# RZN2H register map
Vendor: Renesas Electronics Corporation; Series: RZN; File version: 1.00.00
CPU: other r0p0, little endian, MPU, no FPU, VTOR, 4 interrupt priority bits, 624 interrupts
Registers are 32-bit, read-write, reset 0x0 unless marked. A register's access mark holds for its fields unless they carry their own. Offsets are from the block's base; [hi:lo] are bit positions; {n}, {i} and the like mark numbered series; 'fields as' and 'values as' point back to an identical list.

## GPT09_0 (part 1 of 2) — General PWM Timer 09
Base 0x80000000
Same registers: GPT09_1 0x80000100, GPT09_2 0x80000200, GPT09_3 0x80000300, GPT09_4 0x80000400, GPT09_5 0x80000500, GPT09_6 0x80000600, GPT00_0 0x90002000, GPT00_1 0x90002100, GPT00_2 0x90002200, GPT00_3 0x90002300, GPT00_4 0x90002400, GPT01_0 0x90003000, GPT01_1 0x90003100, GPT01_2 0x90003200, GPT01_3 0x90003300, GPT01_4 0x90003400, GPT02_0 0x90004000, GPT02_1 0x90004100, GPT02_2 0x90004200, GPT02_3 0x90004300, GPT02_4 0x90004400, GPT03_0 0x90005000, GPT03_1 0x90005100, GPT03_2 0x90005200, GPT03_3 0x90005300, GPT03_4 0x90005400, GPT04_0 0x90006000, GPT04_1 0x90006100, GPT04_2 0x90006200, GPT04_3 0x90006300, GPT04_4 0x90006400, GPT05_0 0x90007000, GPT05_1 0x90007100, GPT05_2 0x90007200, GPT05_3 0x90007300, GPT05_4 0x90007400, GPT06_0 0x90100000, GPT06_1 0x90100100, GPT06_2 0x90100200, GPT06_3 0x90100300, GPT06_4 0x90100400, GPT07_0 0x90101000, GPT07_1 0x90101100, GPT07_2 0x90101200, GPT07_3 0x90101300, GPT07_4 0x90101400, GPT08_0 0x90102000, GPT08_1 0x90102100, GPT08_2 0x90102200, GPT08_3 0x90102300, GPT08_4 0x90102400
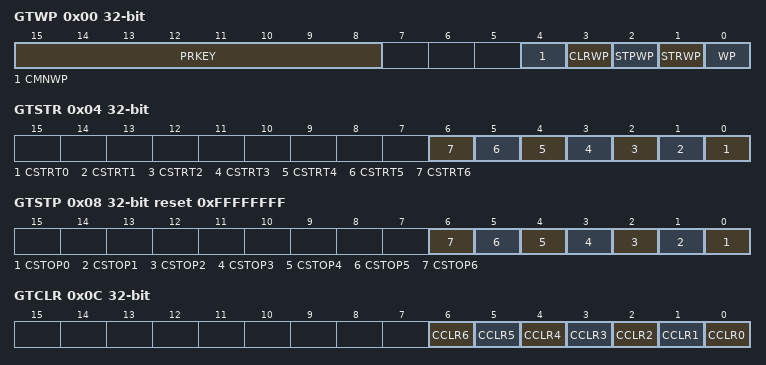
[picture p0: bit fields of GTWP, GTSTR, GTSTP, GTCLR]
0x00 GTWP — General PWM Timer Write-Protection Register
  [15:8] PRKEY wo — GTWP Key Code
  [4] CMNWP — Common Register Write Disabled
    0=Write to the register is enabled; 1=Write to the register is disabled
  [3] CLRWP — GTCLR.CCLR Bit Write Disabled
    0=Write to the bit is enabled; 1=Write to the bit is disabled
  [2] STPWP — GTSTP.CSTOP Bit Write Disabled
    values as CLRWP
  [1] STRWP — GTSTR.CSTRT Bit Write Disabled
    values as CLRWP
  [0] WP — Register Write Disabled
    values as CMNWP
0x04 GTSTR — General PWM Timer Software Start Register
  [all] fields
    0=(Reading) The counter is stopped (Writing) No effect; 1=(Reading) The counter is running (Writing) The counter starts running
  [n] CSTRT{n} (n=0..6) — Channel {n} Count Start
0x08 GTSTP reset 0xFFFFFFFF — General PWM Timer Software Stop Register
  [all] fields
    0=(Reading) The counter is operating (Writing) No effect; 1=(Reading) The counter is stopped (Writing) The counter is stopped
  [n] CSTOP{n} (n=0..6) — Channel {n} Count Stop
0x0C GTCLR wo — General PWM Timer Software Clear Register
  [all] fields
    0=The counter is not cleared; 1=The counter is cleared
  [n] CCLR{n} (n=0..6) — Channel {n} Count Clear
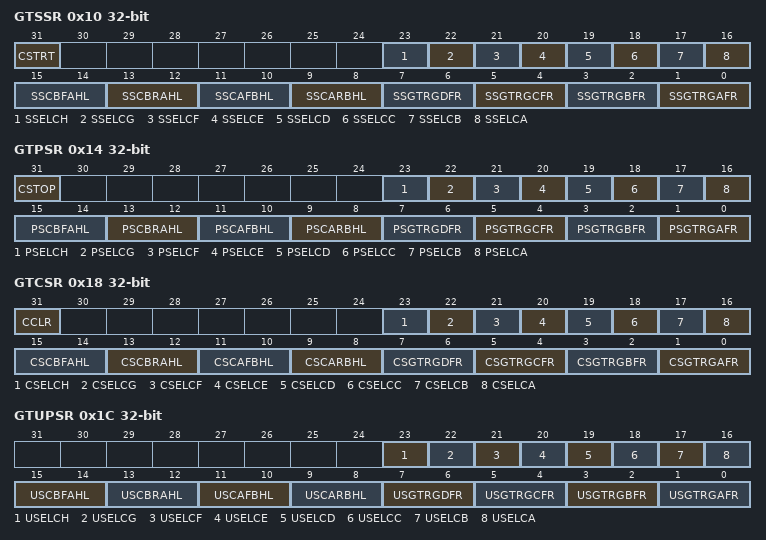
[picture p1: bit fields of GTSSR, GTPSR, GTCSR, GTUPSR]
0x10 GTSSR — General PWM Timer Start Source Select Register
  [31] CSTRT — Software Source Count Start Enable
    0=Disables count start by the GTSTR register; 1=Enables count start by the GTSTR register
  [23] SSELCH
    0=Disables count start by the event H input; 1=Enables count start by the event H input
  [22] SSELCG
    0=Disables count start by the event G input; 1=Enables count start by the event G input
  [21] SSELCF
    0=Disables count start by the event F input; 1=Enables count start by the event F input
  [20] SSELCE
    0=Disables count start by the event E input; 1=Enables count start by the event E input
  [19] SSELCD
    0=Disables count start by the event D input; 1=Enables count start by the event D input
  [18] SSELCC
    0=Disables count start by the event C input; 1=Enables count start by the event C input
  [17] SSELCB
    0=Disables count start by the event B input; 1=Enables count start by the event B input
  [16] SSELCA
    0=Disables count start by the event A input; 1=Enables count start by the event A input
  [15:14] SSCBFAHL
    0=Falling edge of the GTIOCm_nB signal is not used as a trigger to start counting; 1=The counter starts at a falling edge of the GTIOCm_nB signal while the GTIOCm_nA pin is driven low; 2=The counter starts at a falling edge of the GTIOCm_nB signal while the GTIOCm_nA pin is driven high; 3=The counter starts at a falling edge of the GTIOCm_nB signal
  [13:12] SSCBRAHL
    0=Rising edge of the GTIOCm_nB signal is not used as a trigger to start counting; 1=The counter starts at a rising edge of the GTIOCm_nB signal while the GTIOCm_nA pin is driven low; 2=The counter starts at a rising edge of the GTIOCm_nB signal while the GTIOCm_nA pin is driven high; 3=The counter starts at a rising edge of the GTIOCm_nB signal
  [11:10] SSCAFBHL
    0=Falling edge of the GTIOCm_nA signal is not used as a trigger to start counting; 1=The counter starts at a falling edge of the GTIOCm_nA signal while the GTIOCm_nB pin is driven low; 2=The counter starts at a falling edge of the GTIOCm_nA signal while the GTIOCm_nB pin is driven high; 3=The counter starts at a falling edge of the GTIOCm_nA signal
  [9:8] SSCARBHL
    0=Rising edge of the GTIOCm_nA signal is not used as a trigger to start counting; 1=The counter starts at a rising edge of the GTIOCm_nA signal while the GTIOCm_nB pin is driven low; 2=The counter starts at a rising edge of the GTIOCm_nA signal while the GTIOCm_nB pin is driven high; 3=The counter starts at a rising edge of the GTIOCm_nA signal
  [7:6] SSGTRGDFR
    0=The GTETRGD signal is not used as a trigger to start counting; 1=The counter starts at a rising edge of the GTETRGD signal; 2=The counter starts at a falling edge of the GTETRGD signal; 3=The counter starts at both edges of the GTETRGD signal
  [5:4] SSGTRGCFR
    0=The GTETRGC signal is not used as a trigger to start counting; 1=The counter starts at a rising edge of the GTETRGC signal; 2=The counter starts at a falling edge of the GTETRGC signal; 3=The counter starts at both edges of the GTETRGC signal
  [3:2] SSGTRGBFR
    0=The GTETRGB signal is not used as a trigger to start counting; 1=The counter starts at a rising edge of the GTETRGB signal; 2=The counter starts at a falling edge of the GTETRGB signal; 3=The counter starts at both edges of the GTETRGB signal
  [1:0] SSGTRGAFR
    0=The GTETRGA signal is not used as a trigger to start counting; 1=The counter starts at a rising edge of the GTETRGA signal; 2=The counter starts at a falling edge of the GTETRGA signal; 3=The counter starts at both edges of the GTETRGA signal
0x14 GTPSR — General PWM Timer Stop Source Select Register
  [31] CSTOP
    0=Disables count stop by the GTSTP register; 1=Enables count stop by the GTSTP register
  [23] PSELCH
    0=Disables count stop by the event H input; 1=Enables count stop by the event H input
  [22] PSELCG
    0=Disables count stop by the event G input; 1=Enables count stop by the event G input
  [21] PSELCF
    0=Disables count stop by the event F input; 1=Enables count stop by the event F input
  [20] PSELCE
    0=Disables count stop by the event E input; 1=Enables count stop by the event E input
  [19] PSELCD
    0=Disables count stop by the event D input; 1=Enables count stop by the event D input
  [18] PSELCC
    0=Disables count stop by the event C input; 1=Enables count stop by the event C input
  [17] PSELCB
    0=Disables count stop by the event B input; 1=Enables count stop by the event B input
  [16] PSELCA
    0=Disables count stop by the event A input; 1=Enables count stop by the event A input
  [15:14] PSCBFAHL
    0=Falling edge of the GTIOCm_nB signal is not used as a trigger to stop counting; 1=The counter stops at a falling edge of the GTIOCm_nB signal while the GTIOCm_nA pin is driven low; 2=The counter stops at a falling edge of the GTIOCm_nB signal while the GTIOCm_nA pin is driven high; 3=The counter stops at a falling edge of the GTIOCm_nB signal
  [13:12] PSCBRAHL
    0=Rising edge of the GTIOCm_nB signal is not used as a trigger to stop counting; 1=The counter stops at a rising edge of the GTIOCm_nB signal while the GTIOCm_nA pin is driven low; 2=The counter stops at a rising edge of the GTIOCm_nB signal while the GTIOCm_nA pin is driven high; 3=The counter stops at a rising edge of the GTIOCm_nB signal
  [11:10] PSCAFBHL
    0=Falling edge of the GTIOCm_nA signal is not used as a trigger to stop counting; 1=The counter stops at a falling edge of the GTIOCm_nA signal while the GTIOCm_nB pin is driven low; 2=The counter stops at a falling edge of the GTIOCm_nA signal while the GTIOCm_nB pin is driven high; 3=The counter stops at a falling edge of the GTIOCm_nA signal
  [9:8] PSCARBHL
    0=Rising edge of the GTIOCm_nA signal is not used as a trigger to stop counting; 1=The counter stops at a rising edge of the GTIOCm_nA signal while the GTIOCm_nB pin is driven low; 2=The counter stops at a rising edge of the GTIOCm_nA signal while the GTIOCm_nB pin is driven high; 3=The counter stops at a rising edge of the GTIOCm_nA signal
  [7:6] PSGTRGDFR
    0=The GTETRGD signal is not used as a trigger to stop counting; 1=The counter stops at a rising edge of the GTETRGD signal; 2=The counter stops at a falling edge of the GTETRGD signal; 3=The counter stops at both edges of the GTETRGD signal
  [5:4] PSGTRGCFR
    0=The GTETRGC signal is not used as a trigger to stop counting; 1=The counter stops at a rising edge of the GTETRGC signal; 2=The counter stops at a falling edge of the GTETRGC signal; 3=The counter stops at both edges of the GTETRGC signal
  [3:2] PSGTRGBFR
    0=The GTETRGB signal is not used as a trigger to stop counting; 1=The counter stops at a rising edge of the GTETRGB signal; 2=The counter stops at a falling edge of the GTETRGB signal; 3=The counter stops at both edges of the GTETRGB signal
  [1:0] PSGTRGAFR
    0=The GTETRGA signal is not used as a trigger to stop counting; 1=The counter stops at a rising edge of the GTETRGA signal; 2=The counter stops at a falling edge of the GTETRGA signal; 3=The counter stops at both edges of the GTETRGA signal
0x18 GTCSR — General PWM Timer Clear Source Select Register
  [31] CCLR
    0=Disables counter clear by the GTCLR register; 1=Enables counter clear by the GTCLR register
  [23] CSELCH
    0=Disables counter clear by the event H input; 1=Enables counter clear by the event H input
  [22] CSELCG
    0=Disables counter clear by the event G input; 1=Enables counter clear by the event G input
  [21] CSELCF
    0=Disables counter clear by the event F input; 1=Enables counter clear by the event F input
  [20] CSELCE
    0=Disables counter clear by the event E input; 1=Enables counter clear by the event E input
  [19] CSELCD
    0=Disables counter clear by the event D input; 1=Enables counter clear by the event D input
  [18] CSELCC
    0=Disables counter clear by the event C input; 1=Enables counter clear by the event C input
  [17] CSELCB
    0=Disables counter clear by the event B input; 1=Enables counter clear by the event B input
  [16] CSELCA
    0=Disables counter clear by the event A input; 1=Enables counter clear by the event A input
  [15:14] CSCBFAHL
    0=Falling edge of the GTIOCm_nB signal is not used as a trigger to clear the counter; 1=The counter is cleared at a falling edge of the GTIOCm_nB signal while the GTIOCm_nA pin is driven low; 2=The counter is cleared at a falling edge of the GTIOCm_nB signal while the GTIOCm_nA pin is driven high; 3=The counter is cleared at a falling edge of the GTIOCm_nB signal
  [13:12] CSCBRAHL
    0=Rising edge of the GTIOCm_nB signal is not used as a trigger to clear the counter; 1=The counter is cleared at a rising edge of the GTIOCm_nB signal while the GTIOCm_nA pin is driven low; 2=The counter is cleared at a rising edge of the GTIOCm_nB signal while the GTIOCm_nA pin is driven high; 3=The counter is cleared at a rising edge of the GTIOCm_nB signal
  [11:10] CSCAFBHL
    0=Falling edge of the GTIOCm_nA signal is not used as a trigger to clear the counter; 1=The counter is cleared at a falling edge of the GTIOCm_nA signal while the GTIOCm_nB pin is driven low; 2=The counter is cleared at a falling edge of the GTIOCm_nA signal while the GTIOCm_nB pin is driven high; 3=The counter is cleared at a falling edge of the GTIOCm_nA signal
  [9:8] CSCARBHL
    0=Rising edge of the GTIOCm_nA signal is not used as a trigger to clear the counter; 1=The counter is cleared at a rising edge of the GTIOCm_nA signal while the GTIOCm_nB pin is driven low; 2=The counter is cleared at a rising edge of the GTIOCm_nA signal while the GTIOCm_nB pin is driven high; 3=The counter is cleared at a rising edge of the GTIOCm_nA signal
  [7:6] CSGTRGDFR
    0=The GTETRGD signal is not used as a trigger to clear the counter; 1=The counter is cleared at a rising edge of the GTETRGD signal; 2=The counter is cleared at a falling edge of the GTETRGD signal; 3=The counter is cleared at both edges of the GTETRGD signal
  [5:4] CSGTRGCFR
    0=The GTETRGC signal is not used as a trigger to clear the counter; 1=The counter is cleared at a rising edge of the GTETRGC signal; 2=The counter is cleared at a falling edge of the GTETRGC signal; 3=The counter is cleared at both edges of the GTETRGC signal
  [3:2] CSGTRGBFR
    0=The GTETRGB signal is not used as a trigger to clear the counter; 1=The counter is cleared at a rising edge of the GTETRGB signal; 2=The counter is cleared at a falling edge of the GTETRGB signal; 3=The counter is cleared at both edges of the GTETRGB signal
  [1:0] CSGTRGAFR
    0=The GTETRGA signal is not used as a trigger to clear the counter; 1=The counter is cleared at a rising edge of the GTETRGA signal; 2=The counter is cleared at a falling edge of the GTETRGA signal; 3=The counter is cleared at both edges of the GTETRGA signal
0x1C GTUPSR — General PWM Timer Count-Up Source Select Register
  [23] USELCH
    0=Disables count-up by the event H input; 1=Enables count-up by the event H input
  [22] USELCG
    0=Disables count-up by the event G input; 1=Enables count-up by the event G input
  [21] USELCF
    0=Disables count-up by the event F input; 1=Enables count-up by the event F input
  [20] USELCE
    0=Disables count-up by the event E input; 1=Enables count-up by the event E input
  [19] USELCD
    0=Disables count-up by the event D input; 1=Enables count-up by the event D input
  [18] USELCC
    0=Disables count-up by the event C input; 1=Enables count-up by the event C input
  [17] USELCB
    0=Disables count-up by the event B input; 1=Enables count-up by the event B input
  [16] USELCA
    0=Disables count-up by the event A input; 1=Enables count-up by the event A input
  [15:14] USCBFAHL
    0=Falling edge of the GTIOCm_nB signal is not used as a trigger to increment the counter; 1=The counter is incremented at a falling edge of the GTIOCm_nB signal while the GTIOCm_nA pin is driven low; 2=The counter is incremented at a falling edge of the GTIOCm_nB signal while the GTIOCm_nA pin is driven high; 3=The counter is incremented at a falling edge of the GTIOCm_nB signal
  [13:12] USCBRAHL
    0=Rising edge of the GTIOCm_nB signal is not used as a trigger to increment the counter; 1=The counter is incremented at a rising edge of the GTIOCm_nB signal while the GTIOCm_nA pin is driven low; 2=The counter is incremented at a rising edge of the GTIOCm_nB signal while the GTIOCm_nA pin is driven high; 3=The counter is incremented at a rising edge of the GTIOCm_nB signal
  [11:10] USCAFBHL
    0=Falling edge of the GTIOCm_nA signal is not used as a trigger to increment the counter; 1=The counter is incremented at a falling edge of the GTIOCm_nA signal while the GTIOCm_nB pin is driven low; 2=The counter is incremented at a falling edge of the GTIOCm_nA signal while the GTIOCm_nB pin is driven high; 3=The counter is incremented at a falling edge of the GTIOCm_nA signal
  [9:8] USCARBHL
    0=Rising edge of the GTIOCm_nA signal is not used as a trigger to increment the counter; 1=The counter is incremented at a rising edge of the GTIOCm_nA signal while the GTIOCm_nB pin is driven low; 2=The counter is incremented at a rising edge of the GTIOCm_nA signal while the GTIOCm_nB pin is driven high; 3=The counter is incremented at a rising edge of the GTIOCm_nA signal
  [7:6] USGTRGDFR
    0=The GTETRGD signal is not used as a trigger to increment the counter; 1=The counter is incremented at a rising edge of the GTETRGD signal; 2=The counter is incremented at a falling edge of the GTETRGD signal; 3=The counter is incremented at both edges of the GTETRGD signal
  [5:4] USGTRGCFR
    0=The GTETRGC signal is not used as a trigger to increment the counter; 1=The counter is incremented at a rising edge of the GTETRGC signal; 2=The counter is incremented at a falling edge of the GTETRGC signal; 3=The counter is incremented at both edges of the GTETRGC signal
  [3:2] USGTRGBFR
    0=The GTETRGB signal is not used as a trigger to increment the counter; 1=The counter is incremented at a rising edge of the GTETRGB signal; 2=The counter is incremented at a falling edge of the GTETRGB signal; 3=The counter is incremented at both edges of the GTETRGB signal
  [1:0] USGTRGAFR
    0=The GTETRGA signal is not used as a trigger to increment the counter; 1=The counter is incremented at a rising edge of the GTETRGA signal; 2=The counter is incremented at a falling edge of the GTETRGA signal; 3=The counter is incremented at both edges of the GTETRGA signal
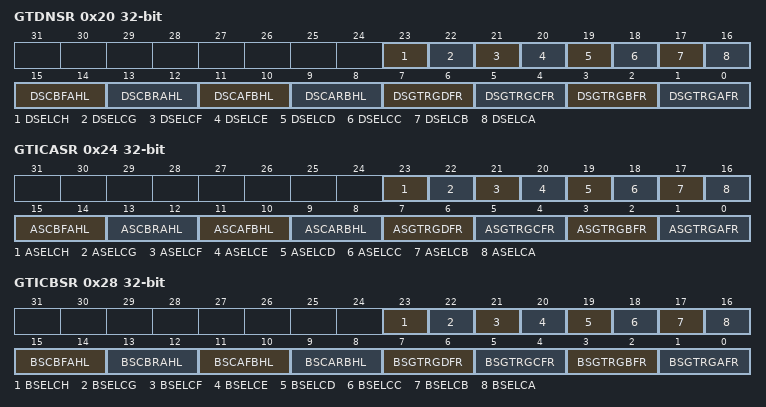
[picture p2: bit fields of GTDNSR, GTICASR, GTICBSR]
0x20 GTDNSR — General PWM Timer Count-Down Source Select Register
  [23] DSELCH
    0=Disables count-down by the event H input; 1=Enables count-down by the event H input
  [22] DSELCG
    0=Disables count-down by the event G input; 1=Enables count-down by the event G input
  [21] DSELCF
    0=Disables count-down by the event F input; 1=Enables count-down by the event F input
  [20] DSELCE
    0=Disables count-down by the event E input; 1=Enables count-down by the event E input
  [19] DSELCD
    0=Disables count-down by the event D input; 1=Enables count-down by the event D input
  [18] DSELCC
    0=Disables count-down by the event C input; 1=Enables count-down by the event C input
  [17] DSELCB
    0=Disables count-down by the event B input; 1=Enables count-down by the event B input
  [16] DSELCA
    0=Disables count-down by the event A input; 1=Enables count-down by the event A input
  [15:14] DSCBFAHL
    0=Falling edge of the GTIOCm_nB signal is not used as a trigger to decrement the counter; 1=The counter is decremented at a falling edge of the GTIOCm_nB signal while the GTIOCm_nA pin is driven low; 2=The counter is decremented at a falling edge of the GTIOCm_nB signal while the GTIOCm_nA pin is driven high; 3=The counter is decremented at a falling edge of the GTIOCm_nB signal
  [13:12] DSCBRAHL
    0=Rising edge of the GTIOCm_nB signal is not used as a trigger to decrement the counter; 1=The counter is decremented at a rising edge of the GTIOCm_nB signal while the GTIOCm_nA pin is driven low; 2=The counter is decremented at a rising edge of the GTIOCm_nB signal while the GTIOCm_nA pin is driven high; 3=The counter is decremented at a rising edge of the GTIOCm_nB signal
  [11:10] DSCAFBHL
    0=Falling edge of the GTIOCm_nA signal is not used as a trigger to decrement the counter; 1=The counter is decremented at a falling edge of the GTIOCm_nA signal while the GTIOCm_nB pin is driven low; 2=The counter is decremented at a falling edge of the GTIOCm_nA signal while the GTIOCm_nB pin is driven high; 3=The counter is decremented at a falling edge of the GTIOCm_nA signal
  [9:8] DSCARBHL
    0=Rising edge of the GTIOCm_nA signal is not used as a trigger to decrement the counter; 1=The counter is decremented at a rising edge of the GTIOCm_nA signal while the GTIOCm_nB pin is driven low; 2=The counter is decremented at a rising edge of the GTIOCm_nA signal while the GTIOCm_nB pin is driven high; 3=The counter is decremented at a rising edge of the GTIOCm_nA signal
  [7:6] DSGTRGDFR
    0=The GTETRGD signal is not used as a trigger to decrement the counter; 1=The counter is decremented at a rising edge of the GTETRGD signal; 2=The counter is decremented at a falling edge of the GTETRGD signal; 3=The counter is decremented at both edges of the GTETRGD signal
  [5:4] DSGTRGCFR
    0=The GTETRGC signal is not used as a trigger to decrement the counter; 1=The counter is decremented at a rising edge of the GTETRGC signal; 2=The counter is decremented at a falling edge of the GTETRGC signal; 3=The counter is decremented at both edges of the GTETRGC signal
  [3:2] DSGTRGBFR
    0=The GTETRGB signal is not used as a trigger to decrement the counter; 1=The counter is decremented at a rising edge of the GTETRGB signal; 2=The counter is decremented at a falling edge of the GTETRGB signal; 3=The counter is decremented at both edges of the GTETRGB signal
  [1:0] DSGTRGAFR
    0=The GTETRGA signal is not used as a trigger to decrement the counter; 1=The counter is decremented at a rising edge of the GTETRGA signal; 2=The counter is decremented at a falling edge of the GTETRGA signal; 3=The counter is decremented at both edges of the GTETRGA signal
0x24 GTICASR — General PWM Timer Input Capture Source Select Register A
  [23] ASELCH
    0=Disables GTCCRA input capture by the event H input; 1=Enables GTCCRA input capture by the event H input
  [22] ASELCG
    0=Disables GTCCRA input capture by the event G input; 1=Enables GTCCRA input capture by the event G input
  [21] ASELCF
    0=Disables GTCCRA input capture by the event F input; 1=Enables GTCCRA input capture by the event F input
  [20] ASELCE
    0=Disables GTCCRA input capture by the event E input; 1=Enables GTCCRA input capture by the event E input
  [19] ASELCD
    0=Disables GTCCRA input capture by the event D input; 1=Enables GTCCRA input capture by the event D input
  [18] ASELCC
    0=Disables GTCCRA input capture by the event C input; 1=Enables GTCCRA input capture by the event C input
  [17] ASELCB
    0=Disables GTCCRA input capture by the event B input; 1=Enables GTCCRA input capture by the event B input
  [16] ASELCA
    0=Disables GTCCRA input capture by the event A input; 1=Enables GTCCRA input capture by the event A input
  [15:14] ASCBFAHL
    0=Falling edge of the GTIOCm_nB signal is not used as a trigger to capture the counter value in the GTCCRA register; 1=The counter value is captured in the GTCCRA register at a falling edge of the GTIOCm_nB signal while the GTIOCm_nA pin is driven low; 2=The counter value is captured in the GTCCRA register at a falling edge of the GTIOCm_nB signal while the GTIOCm_nA pin is driven high; 3=The counter value is captured in the GTCCRA register at a falling edge of the GTIOCm_nB signal
  [13:12] ASCBRAHL
    0=Rising edge of the GTIOCm_nB signal is not used as a trigger to capture the counter value in the GTCCRA register; 1=The counter value is captured in the GTCCRA register at a rising edge of the GTIOCm_nB signal while the GTIOCm_nA pin is driven low; 2=The counter value is captured in the GTCCRA register at a rising edge of the GTIOCm_nB signal while the GTIOCm_nA pin is driven high; 3=The counter value is captured in the GTCCRA register at a rising edge of the GTIOCm_nB signal
  [11:10] ASCAFBHL
    0=Falling edge of the GTIOCm_nA signal is not used as a trigger to capture the counter value in the GTCCRA register; 1=The counter value is captured in the GTCCRA register at a falling edge of the GTIOCm_nA signal while the GTIOCm_nB pin is driven low; 2=The counter value is captured in the GTCCRA register at a falling edge of the GTIOCm_nA signal while the GTIOCm_nB pin is driven high; 3=The counter value is captured in the GTCCRA register at a falling edge of the GTIOCm_nA signal
  [9:8] ASCARBHL
    0=Rising edge of the GTIOCm_nA signal is not used as a trigger to capture the counter value in the GTCCRA register; 1=The counter value is captured in the GTCCRA register at a rising edge of the GTIOCm_nA signal while the GTIOCm_nB pin is driven low; 2=The counter value is captured in the GTCCRA register at a rising edge of the GTIOCm_nA signal while the GTIOCm_nB pin is driven high; 3=The counter value is captured in the GTCCRA register at a rising edge of the GTIOCm_nA signal
  [7:6] ASGTRGDFR
    0=The GTETRGD signal is not used as a trigger to capture the counter value in the GTCCRA register; 1=The counter value is captured in the GTCCRA register at a rising edge of the GTETRGD signal; 2=The counter value is captured in the GTCCRA register at a falling edge of the GTETRGD signal; 3=The counter value is captured in the GTCCRA register at both edges of the GTETRGD signal
  [5:4] ASGTRGCFR
    0=The GTETRGC signal is not used as a trigger to capture the counter value in the GTCCRA register; 1=The counter value is captured in the GTCCRA register at a rising edge of the GTETRGC signal; 2=The counter value is captured in the GTCCRA register at a falling edge of the GTETRGC signal; 3=The counter value is captured in the GTCCRA register at both edges of the GTETRGC signal
  [3:2] ASGTRGBFR
    0=The GTETRGB signal is not used as a trigger to capture the counter value in the GTCCRA register; 1=The counter value is captured in the GTCCRA register at a rising edge of the GTETRGB signal; 2=The counter value is captured in the GTCCRA register at a falling edge of the GTETRGB signal; 3=The counter value is captured in the GTCCRA register at both edges of the GTETRGB signal
  [1:0] ASGTRGAFR
    0=The GTETRGA signal is not used as a trigger to capture the counter value in the GTCCRA register; 1=The counter value is captured in the GTCCRA register at a rising edge of the GTETRGA signal; 2=The counter value is captured in the GTCCRA register at a falling edge of the GTETRGA signal; 3=The counter value is captured in the GTCCRA register at both edges of the GTETRGA signal
0x28 GTICBSR — General PWM Timer Input Capture Source Select Register B
  [23] BSELCH
    0=Disables GTCCRB input capture by the event H input; 1=Enables GTCCRB input capture by the event H input
  [22] BSELCG
    0=Disables GTCCRB input capture by the event G input; 1=Enables GTCCRB input capture by the event G input
  [21] BSELCF
    0=Disables GTCCRB input capture by the event F input; 1=Enables GTCCRB input capture by the event F input
  [20] BSELCE
    0=Disables GTCCRB input capture by the event E input; 1=Enables GTCCRB input capture by the event E input
  [19] BSELCD
    0=Disables GTCCRB input capture by the event D input; 1=Enables GTCCRB input capture by the event D input
  [18] BSELCC
    0=Disables GTCCRB input capture by the event C input; 1=Enables GTCCRB input capture by the event C input
  [17] BSELCB
    0=Disables GTCCRB input capture by the event B input; 1=Enables GTCCRB input capture by the event B input
  [16] BSELCA
    0=Disables GTCCRB input capture by the event A input; 1=Enables GTCCRB input capture by the event A input
  [15:14] BSCBFAHL
    0=Falling edge of the GTIOCm_nB signal is not used as a trigger to capture the counter value in the GTCCRB register; 1=The counter value is captured in the GTCCRB register at a falling edge of the GTIOCm_nB signal while the GTIOCm_nA pin is driven low; 2=The counter value is captured in the GTCCRB register at a falling edge of the GTIOCm_nB signal while the GTIOCm_nA pin is driven high; 3=The counter value is captured in the GTCCRB register at a falling edge of the GTIOCm_nB signal
  [13:12] BSCBRAHL
    0=Rising edge of the GTIOCm_nB signal is not used as a trigger to capture the counter value in the GTCCRB register; 1=The counter value is captured in the GTCCRB register at a rising edge of the GTIOCm_nB signal while the GTIOCm_nA pin is driven low; 2=The counter value is captured in the GTCCRB register at a rising edge of the GTIOCm_nB signal while the GTIOCm_nA pin is driven high; 3=The counter value is captured in the GTCCRB register at a rising edge of the GTIOCm_nB signal
  [11:10] BSCAFBHL
    0=Falling edge of the GTIOCm_nA signal is not used as a trigger to capture the counter value in the GTCCRB register; 1=The counter value is captured in the GTCCRB register at a falling edge of the GTIOCm_nA signal while the GTIOCm_nB pin is driven low; 2=The counter value is captured in the GTCCRB register at a falling edge of the GTIOCm_nA signal while the GTIOCm_nB pin is driven high; 3=The counter value is captured in the GTCCRB register at a falling edge of the GTIOCm_nA signal
  [9:8] BSCARBHL
    0=Rising edge of the GTIOCm_nA signal is not used as a trigger to capture the counter value in the GTCCRB register; 1=The counter value is captured in the GTCCRB register at a rising edge of the GTIOCm_nA signal while the GTIOCm_nB pin is driven low; 2=The counter value is captured in the GTCCRB register at a rising edge of the GTIOCm_nA signal while the GTIOCm_nB pin is driven high; 3=The counter value is captured in the GTCCRB register at a rising edge of the GTIOCm_nA signal
  [7:6] BSGTRGDFR
    0=The GTETRGD signal is not used as a trigger to capture the counter value in the GTCCRB register; 1=The counter value is captured in the GTCCRB register at a rising edge of the GTETRGD signal; 2=The counter value is captured in the GTCCRB register at a falling edge of the GTETRGD signal; 3=The counter value is captured in the GTCCRB register at both edges of the GTETRGD signal
  [5:4] BSGTRGCFR
    0=The GTETRGC signal is not used as a trigger to capture the counter value in the GTCCRB register; 1=The counter value is captured in the GTCCRB register at a rising edge of the GTETRGC signal; 2=The counter value is captured in the GTCCRB register at a falling edge of the GTETRGC signal; 3=The counter value is captured in the GTCCRB register at both edges of the GTETRGC signal
  [3:2] BSGTRGBFR
    0=The GTETRGB signal is not used as a trigger to capture the counter value in the GTCCRB register; 1=The counter value is captured in the GTCCRB register at a rising edge of the GTETRGB signal; 2=The counter value is captured in the GTCCRB register at a falling edge of the GTETRGB signal; 3=The counter value is captured in the GTCCRB register at both edges of the GTETRGB signal
  [1:0] BSGTRGAFR
    0=The GTETRGA signal is not used as a trigger to capture the counter value in the GTCCRB register; 1=The counter value is captured in the GTCCRB register at a rising edge of the GTETRGA signal; 2=The counter value is captured in the GTCCRB register at a falling edge of the GTETRGA signal; 3=The counter value is captured in the GTCCRB register at both edges of the GTETRGA signal

## GPT10_0 (part 1 of 2) — General PWM Timer 10
Base 0x81000000
Same registers: GPT10_1 0x81000100, GPT10_2 0x81000200, GPT10_3 0x81000300
Registers as GPT09_0.
